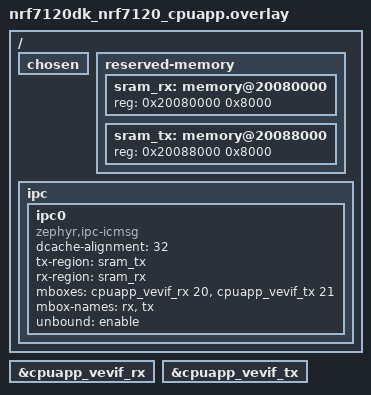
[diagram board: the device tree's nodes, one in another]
/*
 * Copyright (c) 2026 Nordic Semiconductor ASA
 *
 * SPDX-License-Identifier: LicenseRef-Nordic-5-Clause
 */

/ {
	chosen {
		/delete-property/ zephyr,bt-hci;
	};

	reserved-memory {
		#address-cells = <1>;
		#size-cells = <1>;
		ranges;

		sram_rx: memory@20080000 {
			reg = <0x20080000 0x8000>;
		};

		sram_tx: memory@20088000 {
			reg = <0x20088000 0x8000>;
		};
	};

	ipc {
		ipc0: ipc0 {
			compatible = "zephyr,ipc-icmsg";
			dcache-alignment = <32>;
			tx-region = <&sram_tx>;
			rx-region = <&sram_rx>;
			mboxes = <&cpuapp_vevif_rx 20>, <&cpuapp_vevif_tx 21>;
			mbox-names = "rx", "tx";
			unbound = "enable";
			status = "okay";
		};
	};
};

&cpuapp_vevif_rx {
	status = "okay";
};

&cpuapp_vevif_tx {
	status = "okay";
};
